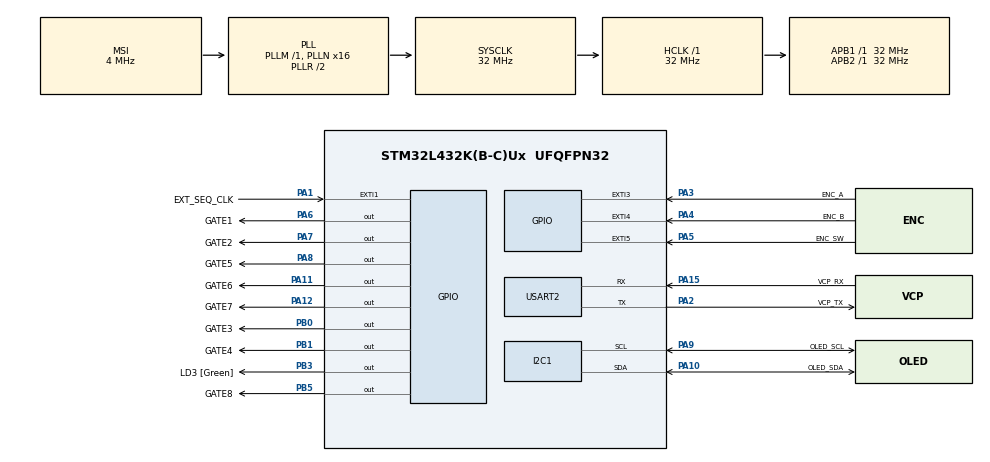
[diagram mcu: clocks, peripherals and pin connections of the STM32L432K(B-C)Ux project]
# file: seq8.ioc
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Mcu.Family=STM32L4
RCC.CortexFreq_Value=32000000
PA0.GPIO_Label=MCO [High speed clock in]
NVIC.EXTI3_IRQn=true\:4\:0\:true\:false\:true\:true\:true
PA6.GPIO_Label=GATE1
PB0.GPIO_Label=GATE3
PA15\ (JTDI).Signal=USART2_RX
PC15-OSC32_OUT\ (PC15).Mode=LSE-External-Oscillator
RCC.SYSCLKSource=RCC_SYSCLKSOURCE_PLLCLK
ProjectManager.StackSize=0x400
PB3\ (JTDO-TRACESWO).Signal=GPIO_Output
PC14-OSC32_IN\ (PC14).Mode=LSE-External-Oscillator
PA14\ (JTCK-SWCLK).Signal=SYS_JTCK-SWCLK
PA15\ (JTDI).Mode=Asynchronous
NVIC.EXTI1_IRQn=true\:5\:0\:true\:false\:true\:true\:true
PA12.Signal=GPIO_Output
Mcu.UserConstants=SEQ_CLOCK,TIM2
RCC.HCLKFreq_Value=32000000
RCC.APB2TimFreq_Value=32000000
RCC.AHBFreq_Value=32000000
RCC.HSE_VALUE=8000000
USART2.VirtualMode-Asynchronous=VM_ASYNC
RCC.PLLMUL=RCC_PLLMUL_4
PB1.GPIO_Label=GATE4
NVIC.TIM2_IRQn=true\:0\:0\:false\:false\:true\:true\:true
PA10.GPIO_Label=OLED_SDA
PA0.Mode=HSE-External-Clock-Source-for-LittleOrca
PA8.Signal=GPIO_Output
PA0.Signal=RCC_CK_IN
Mcu.Package=UFQFPN32
PB1.Signal=GPIO_Output
PA6.Signal=GPIO_Output
PA2.GPIO_Label=VCP_TX
PA10.Signal=I2C1_SDA
PB5.GPIO_Label=GATE8
RCC.APB1TimFreq_Value=32000000
PA13\ (JTMS-SWDIO).Signal=SYS_JTMS-SWDIO
PA4.GPIO_Label=ENC_B
RCC.HSI48_VALUE=48000000
PA3.Signal=GPXTI3
RCC.MSI_VALUE=4000000
PA14\ (JTCK-SWCLK).Mode=Serial_Wire
NVIC.EXTI4_IRQn=true\:4\:0\:true\:false\:true\:true\:true
PA10.Mode=I2C
PA9.GPIO_Label=OLED_SCL
PA11.GPIO_Label=GATE6
PC15-OSC32_OUT\ (PC15).Signal=RCC_OSC32_OUT
PA14\ (JTCK-SWCLK).GPIO_Label=SWCLK
PB3\ (JTDO-TRACESWO).GPIO_Label=LD3 [Green]
PA12.GPIO_Label=GATE7
PA3.GPIO_ModeDefaultEXTI=GPIO_MODE_IT_RISING_FALLING
RCC.HSI16_VALUE=16000000
PA9.Mode=I2C
PA8.GPIO_Label=GATE5
ProjectManager.TargetToolchain=STM32CubeIDE
PA9.Signal=I2C1_SCL
I2C1.Timing=0x00707CBB
PA4.GPIO_ModeDefaultEXTI=GPIO_MODE_IT_RISING_FALLING
PA1.Signal=GPXTI1
PA5.Signal=GPXTI5
board=NUCLEO-L432KC
RCC.VCOOutputFreq_Value=64000000
RCC.APB2Freq_Value=32000000
PA13\ (JTMS-SWDIO).GPIO_Label=SWDIO
VP_TIM2_VS_ClockSourceINT.Mode=Internal
PA1.GPIO_Label=EXT_SEQ_CLK
PA15\ (JTDI).GPIO_Label=VCP_RX
Mcu.Name=STM32L432K(B-C)Ux
PA2.Signal=USART2_TX
PA13\ (JTMS-SWDIO).Mode=Serial_Wire
PA4.Signal=GPXTI4
RCC.SYSCLKFreq_VALUE=32000000
PB5.Signal=GPIO_Output
PA7.GPIO_Label=GATE2
PA5.GPIO_Label=ENC_SW
PC14-OSC32_IN\ (PC14).Signal=RCC_OSC32_IN
PA11.Signal=GPIO_Output
NVIC.EXTI9_5_IRQn=true\:4\:0\:true\:false\:true\:true\:true
ProjectManager.HeapSize=0x200
RCC.HSI_VALUE=16000000
NVIC.PriorityGroup=NVIC_PRIORITYGROUP_4
RCC.PLLN=16
PA2.Mode=Asynchronous
RCC.APB1Freq_Value=32000000
PB0.Signal=GPIO_Output
PA3.GPIO_Label=ENC_A
PA7.Signal=GPIO_Output

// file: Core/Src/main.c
/* USER CODE BEGIN Header */
/**
  ******************************************************************************
  * @file           : main.c
  * @brief          : Main program body
  ******************************************************************************
  * @attention
  *
  * <h2><center>&copy; Copyright (c) 2021 STMicroelectronics.
  * All rights reserved.</center></h2>
  *
  * This software component is licensed by ST under BSD 3-Clause license,
  * the "License"; You may not use this file except in compliance with the
  * License. You may obtain a copy of the License at:
  *                        opensource.org/licenses/BSD-3-Clause
  *
  ******************************************************************************
  */
/* USER CODE END Header */
#include "main.h"
#include "i2c.h"
#include "tim.h"
#include "usart.h"
#include "gpio.h"

/* USER CODE BEGIN Includes */
#include <App.h>
/* USER CODE END Includes */

void SystemClock_Config(void);

int main(void)
{

  /* MCU Configuration--------------------------------------------------------*/

  /* Reset of all peripherals, Initializes the Flash interface and the Systick. */
  HAL_Init();

  /* Configure the system clock */
  SystemClock_Config();

  /* Initialize all configured peripherals */
  MX_GPIO_Init();
  MX_USART2_UART_Init();
  MX_I2C1_Init();
  MX_TIM2_Init();

  /* Infinite loop */
  /* USER CODE BEGIN WHILE */
  AppRun(); // Never returns
    /* USER CODE END WHILE */

}

void SystemClock_Config(void)
{
  RCC_OscInitTypeDef RCC_OscInitStruct = {0};
  RCC_ClkInitTypeDef RCC_ClkInitStruct = {0};
  RCC_PeriphCLKInitTypeDef PeriphClkInit = {0};

  /** Configure LSE Drive Capability
  */
  HAL_PWR_EnableBkUpAccess();
  __HAL_RCC_LSEDRIVE_CONFIG(RCC_LSEDRIVE_LOW);
  /** Initializes the RCC Oscillators according to the specified parameters
  * in the RCC_OscInitTypeDef structure.
  */
  RCC_OscInitStruct.OscillatorType = RCC_OSCILLATORTYPE_LSE|RCC_OSCILLATORTYPE_MSI;
  RCC_OscInitStruct.LSEState = RCC_LSE_ON;
  RCC_OscInitStruct.MSIState = RCC_MSI_ON;
  RCC_OscInitStruct.MSICalibrationValue = 0;
  RCC_OscInitStruct.MSIClockRange = RCC_MSIRANGE_6;
  RCC_OscInitStruct.PLL.PLLState = RCC_PLL_ON;
  RCC_OscInitStruct.PLL.PLLSource = RCC_PLLSOURCE_MSI;
  RCC_OscInitStruct.PLL.PLLM = 1;
  RCC_OscInitStruct.PLL.PLLN = 16;
  RCC_OscInitStruct.PLL.PLLP = RCC_PLLP_DIV7;
  RCC_OscInitStruct.PLL.PLLQ = RCC_PLLQ_DIV2;
  RCC_OscInitStruct.PLL.PLLR = RCC_PLLR_DIV2;
  if (HAL_RCC_OscConfig(&RCC_OscInitStruct) != HAL_OK)
  {
    Error_Handler();
  }
  /** Initializes the CPU, AHB and APB buses clocks
  */
  RCC_ClkInitStruct.ClockType = RCC_CLOCKTYPE_HCLK|RCC_CLOCKTYPE_SYSCLK
                              |RCC_CLOCKTYPE_PCLK1|RCC_CLOCKTYPE_PCLK2;
  RCC_ClkInitStruct.SYSCLKSource = RCC_SYSCLKSOURCE_PLLCLK;
  RCC_ClkInitStruct.AHBCLKDivider = RCC_SYSCLK_DIV1;
  RCC_ClkInitStruct.APB1CLKDivider = RCC_HCLK_DIV1;
  RCC_ClkInitStruct.APB2CLKDivider = RCC_HCLK_DIV1;

  if (HAL_RCC_ClockConfig(&RCC_ClkInitStruct, FLASH_LATENCY_1) != HAL_OK)
  {
    Error_Handler();
  }
  PeriphClkInit.PeriphClockSelection = RCC_PERIPHCLK_USART2|RCC_PERIPHCLK_I2C1;
  PeriphClkInit.Usart2ClockSelection = RCC_USART2CLKSOURCE_PCLK1;
  PeriphClkInit.I2c1ClockSelection = RCC_I2C1CLKSOURCE_PCLK1;
  if (HAL_RCCEx_PeriphCLKConfig(&PeriphClkInit) != HAL_OK)
  {
    Error_Handler();
  }
  /** Configure the main internal regulator output voltage
  */
  if (HAL_PWREx_ControlVoltageScaling(PWR_REGULATOR_VOLTAGE_SCALE1) != HAL_OK)
  {
    Error_Handler();
  }
  /** Enable MSI Auto calibration
  */
  HAL_RCCEx_EnableMSIPLLMode();
}

void Error_Handler(void)
{
  __disable_irq();
  while (1)
  {
  }
}

/************************ (C) COPYRIGHT STMicroelectronics *****END OF FILE****/
